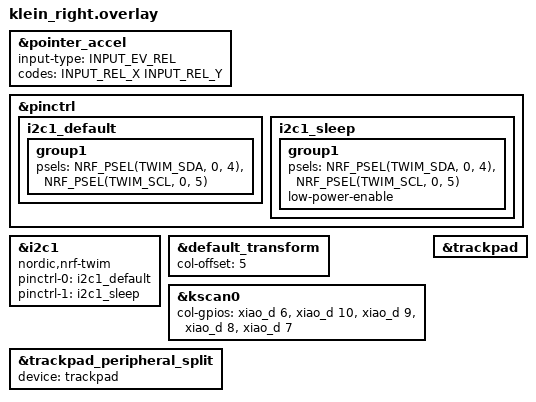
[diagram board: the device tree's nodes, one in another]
/*
 * Copyright (c) 2020 Derek Schmell
 *
 * SPDX-License-Identifier: MIT
 */

#include "klein.dtsi"
#include <input/processors.dtsi>
#include <behaviors/input_gestures_accel.dtsi>

&pointer_accel {
    input-type = <INPUT_EV_REL>;
    codes = <INPUT_REL_X INPUT_REL_Y>;
    // Preset values are automatically applied!
};

&pinctrl {
    i2c1_default: i2c1_default {
        group1 {
            psels = <NRF_PSEL(TWIM_SDA, 0, 4)>,
                    <NRF_PSEL(TWIM_SCL, 0, 5)>;
        };
    };

    i2c1_sleep: i2c1_sleep {
        group1 {
            psels = <NRF_PSEL(TWIM_SDA, 0, 4)>,
                    <NRF_PSEL(TWIM_SCL, 0, 5)>;
            low-power-enable;
        };
    };
};

&i2c1 {
    status = "okay";
    compatible = "nordic,nrf-twim";
    pinctrl-0 = <&i2c1_default>;
    pinctrl-1 = <&i2c1_sleep>;
    pinctrl-names = "default", "sleep";
};

&default_transform {
	col-offset = <5>;
};

&kscan0 {
    col-gpios
        = <&xiao_d 6  (GPIO_ACTIVE_HIGH | GPIO_PULL_DOWN)>
        , <&xiao_d 10  (GPIO_ACTIVE_HIGH | GPIO_PULL_DOWN)>
        , <&xiao_d 9  (GPIO_ACTIVE_HIGH | GPIO_PULL_DOWN)>
        , <&xiao_d 8  (GPIO_ACTIVE_HIGH | GPIO_PULL_DOWN)>
        , <&xiao_d 7  (GPIO_ACTIVE_HIGH | GPIO_PULL_DOWN)>
        ;
};

&trackpad {
    status = "okay";
};

&trackpad_peripheral_split {
    device = <&trackpad>;
};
